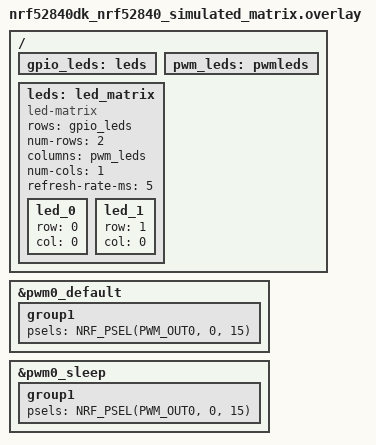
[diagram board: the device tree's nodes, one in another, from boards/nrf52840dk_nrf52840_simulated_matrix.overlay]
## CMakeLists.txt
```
# SPDX-License-Identifier: Apache-2.0

cmake_minimum_required(VERSION 3.20.0)

find_package(Zephyr REQUIRED HINTS $ENV{ZEPHYR_BASE})
project(led_basic)

FILE(GLOB app_sources src/*.c)
target_sources(app PRIVATE ${app_sources})
```

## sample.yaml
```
sample:
  description: Demonstration of an LED driver
  name: Basic LED sample
tests:
  sample.drivers.led.basic:
    tags: led
    platform_allow:
      - nrf52840dk/nrf52840
    integration_platforms:
      - nrf52840dk/nrf52840
    build_only: true

  sample.drivers.led.basic.nrf52840dk_matrix:
    tags: led
    platform_allow:
      - nrf52840dk/nrf52840
    integration_platforms:
      - nrf52840dk/nrf52840
    build_only: true
    extra_args:
      - DTC_OVERLAY_FILE=boards/nrf52840dk_nrf52840_simulated_matrix.overlay
```

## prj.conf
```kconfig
CONFIG_LED=y
```

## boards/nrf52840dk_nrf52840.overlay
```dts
/*
 * Copyright (c) 2026 Hubert Miś
 * SPDX-License-Identifier: Apache-2.0
 */

/ {
	leds: leds {};
};
```

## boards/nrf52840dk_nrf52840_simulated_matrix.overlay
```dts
/*
 * Copyright (c) 2026 Hubert Miś
 * SPDX-License-Identifier: Apache-2.0
 */

/* This overlay simulates an LED matrix on the nRF52840DK, which does not include a native LED
 * matrix but is equipped with 4 individual LEDs.
 * LEDs 1 and 2 simulate the matrix row controllers, while LED 3 simulates the matrix
 * column controller.
 *
 * In this simulation, when any LED is active, LEDs 1 and 2 are expected to blink at
 * a frequency of 100 Hz (appearing steady to the naked eye). LED 3 is expected to activate
 * in conjunction with LED 1, LED 2, or both, depending on which LEDs in the matrix are
 * requested to be illuminated. The difference in LED 3's duty cycle, when activated for one or both
 * rows, is perceptible to the human eye as a slight variation in brightness.
 */

/ {
	gpio_leds: leds {};

	pwm_leds: pwmleds {};

	leds: led_matrix {
		compatible = "led-matrix";

		rows = <&gpio_leds>;
		num-rows = <2>;
		columns = <&pwm_leds>;
		num-cols = <1>;

		refresh-rate-ms = <5>;

		led_0 {
			row = <0>;
			col = <0>;
		};

		led_1 {
			row = <1>;
			col = <0>;
		};
	};
};

&pwm0_default {
	group1 {
		psels = <NRF_PSEL(PWM_OUT0, 0, 15)>;
	};
};

&pwm0_sleep {
	group1 {
		psels = <NRF_PSEL(PWM_OUT0, 0, 15)>;
	};
};
```

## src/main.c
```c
/*
 * Copyright (c) 2026 Hubert Miś
 *
 * SPDX-License-Identifier: Apache-2.0
 */

#include <zephyr/device.h>
#include <zephyr/devicetree.h>
#include <errno.h>
#include <stdint.h>
#include <zephyr/drivers/led.h>
#include <zephyr/sys/util.h>
#include <zephyr/kernel.h>

#include <zephyr/logging/log.h>
LOG_MODULE_REGISTER(main, CONFIG_LOG_DEFAULT_LEVEL);

#define LED_NODE_ID	 DT_NODELABEL(leds)
#define LED_NUM_CHANNELS	DT_CHILD_NUM(LED_NODE_ID)

int main(void)
{
	const struct device *leds;
	uint8_t all_off[LED_NUM_CHANNELS];
	uint8_t all_on[LED_NUM_CHANNELS];
	int ret;

	leds = DEVICE_DT_GET(LED_NODE_ID);
	if (!device_is_ready(leds)) {
		LOG_ERR("Device %s is not ready", leds->name);
		return 0;
	}

	memset(all_off, 0, ARRAY_SIZE(all_off));
	memset(all_on, 100, ARRAY_SIZE(all_on));

	while (1) {
		LOG_INF("Turning on sequence");
		for (int i = 0; i < LED_NUM_CHANNELS; i++) {
			led_on(leds, i);
			k_sleep(K_MSEC(250));
		}
		LOG_INF("Turned on");

		ret = led_write_channels(leds, 0, LED_NUM_CHANNELS, all_off);

		if (ret == -ENOSYS) {
			LOG_INF("led_write_channels is not available");
			k_sleep(K_SECONDS(1));
		} else if (ret < 0) {
			LOG_ERR("led_write_channels returned %d", ret);
		} else {
			LOG_INF("Blinking with led_write_channels");

			k_sleep(K_MSEC(250));
			ret = led_write_channels(leds, 0, LED_NUM_CHANNELS, all_on);

			if (ret < 0) {
				LOG_ERR("led_write_channels returned %d", ret);
			}

			k_sleep(K_MSEC(250));
			ret = led_write_channels(leds, 0, LED_NUM_CHANNELS, all_off);

			if (ret < 0) {
				LOG_ERR("led_write_channels returned %d", ret);
			}

			k_sleep(K_MSEC(250));
			ret = led_write_channels(leds, 0, LED_NUM_CHANNELS, all_on);

			if (ret < 0) {
				LOG_ERR("led_write_channels returned %d", ret);
			}

			k_sleep(K_MSEC(250));
		}

		LOG_INF("Turning off sequence");
		for (int i = 0; i < LED_NUM_CHANNELS; i++) {
			led_off(leds, i);
			k_sleep(K_MSEC(250));
		}
		LOG_INF("Turned off");
	}

	return 0;
}
```
